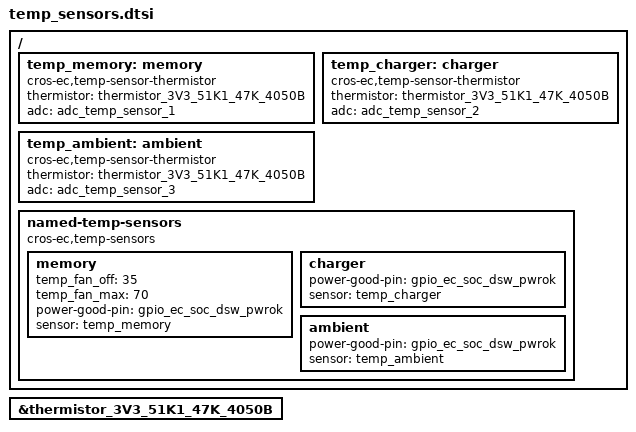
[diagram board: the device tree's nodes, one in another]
/* Copyright 2025 The ChromiumOS Authors
 * Use of this source code is governed by a BSD-style license that can be
 * found in the LICENSE file.
 */

#include <cros/thermistor/thermistor.dtsi>

/ {
	temp_memory: memory {
		compatible = "cros-ec,temp-sensor-thermistor";
		thermistor = <&thermistor_3V3_51K1_47K_4050B>;
		adc = <&adc_temp_sensor_1>;
	};
	temp_charger: charger {
		compatible = "cros-ec,temp-sensor-thermistor";
		thermistor = <&thermistor_3V3_51K1_47K_4050B>;
		adc = <&adc_temp_sensor_2>;
	};
	temp_ambient: ambient {
		compatible = "cros-ec,temp-sensor-thermistor";
		thermistor = <&thermistor_3V3_51K1_47K_4050B>;
		adc = <&adc_temp_sensor_3>;
	};

	named-temp-sensors {
		compatible = "cros-ec,temp-sensors";
		memory {
			temp_fan_off = <35>;
			temp_fan_max = <70>;
			power-good-pin = <&gpio_ec_soc_dsw_pwrok>;
			sensor = <&temp_memory>;
		};
		charger {
			power-good-pin = <&gpio_ec_soc_dsw_pwrok>;
			sensor = <&temp_charger>;
		};
		ambient {
			power-good-pin = <&gpio_ec_soc_dsw_pwrok>;
			sensor = <&temp_ambient>;
		};
	};
};

&thermistor_3V3_51K1_47K_4050B {
	status = "okay";
};
